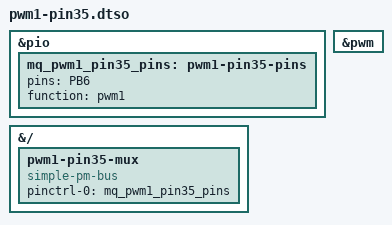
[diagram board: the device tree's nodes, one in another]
// SPDX-License-Identifier: (GPL-2.0+ OR MIT)
// Mangue OS header overlay pwm1-pin35 — GENERATED by tools/gen_overlays.py,
// edit overlays/header_table.py instead.
//
// pin port  role
//  35 PB6   pwm1
// device: /sys/class/pwm/pwmchip0 channel 1

/dts-v1/;
/plugin/;

#include <dt-bindings/gpio/gpio.h>
#include <dt-bindings/interrupt-controller/irq.h>
#include <dt-bindings/input/linux-event-codes.h>

&pio {
	mq_pwm1_pin35_pins: pwm1-pin35-pins {
		pins = "PB6";
		function = "pwm1";
	};
};

&pwm {
	status = "okay";
};

&{/} {
	pwm1-pin35-mux {
		compatible = "simple-pm-bus";
		pinctrl-names = "default";
		pinctrl-0 = <&mq_pwm1_pin35_pins>;
	};
};
